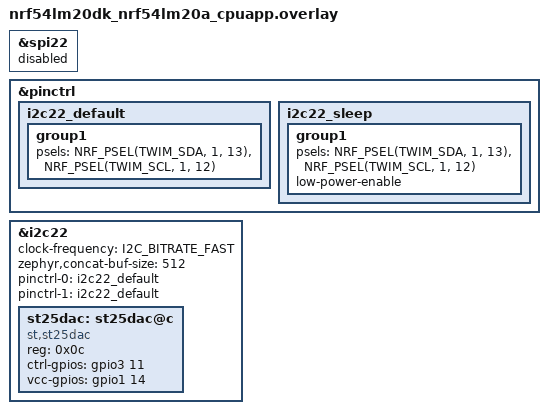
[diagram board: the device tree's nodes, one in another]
/*
 * Copyright (c) 2026 Nordic Semiconductor ASA
 * SPDX-License-Identifier: Apache-2.0
 *
 * ST-NUCLEO-NFC on nRF54LM20 DK (cpuapp b) - manual bench wiring.
 *
 * Wire shield to DK GPIO headers
 *   SDA  -> P1.13  (also on expansion hdr pin 5)
 *   SCL  -> P1.12  (P1 GPIO header only — not on P17 map)
 *   VCC  -> P1.14  (P1 GPIO header)
 *   CTRL -> P3.11  (P5 GPIO header) — BiDir wake; shield has external pull-up
 *   3V3 (direct)
 *   GND (direct)
 *
 */

#include <zephyr/dt-bindings/gpio/nordic-nrf-gpio.h>

&spi22 {
	status = "disabled";
};

&pinctrl {
	i2c22_default: i2c22_default {
		group1 {
			psels = <NRF_PSEL(TWIM_SDA, 1, 13)>,
				<NRF_PSEL(TWIM_SCL, 1, 12)>;
		};
	};

	i2c22_sleep: i2c22_sleep {
		group1 {
			psels = <NRF_PSEL(TWIM_SDA, 1, 13)>,
				<NRF_PSEL(TWIM_SCL, 1, 12)>;
			low-power-enable;
		};
	};
};

&i2c22 {
	status = "okay";
	/delete-property/ zephyr,pm-device-runtime-auto;
	clock-frequency = <I2C_BITRATE_FAST>;
	zephyr,concat-buf-size = <512>;
	pinctrl-0 = <&i2c22_default>;
	pinctrl-1 = <&i2c22_default>;
	pinctrl-names = "default", "sleep";

	st25dac: st25dac@c {
		compatible = "st,st25dac";
		reg = <0x0c>;
		status = "okay";
		ctrl-gpios = <&gpio3 11 (GPIO_OPEN_DRAIN | GPIO_ACTIVE_HIGH)>;
		vcc-gpios = <&gpio1 14 (GPIO_PUSH_PULL | GPIO_ACTIVE_HIGH | NRF_GPIO_DRIVE_H0H1)>;
	};
};
